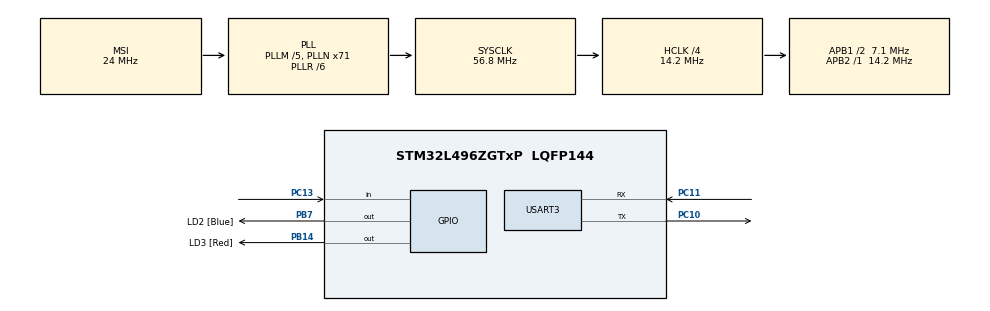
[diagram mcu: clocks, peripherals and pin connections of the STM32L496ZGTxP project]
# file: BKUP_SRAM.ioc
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Mcu.Family=STM32L4
Mcu.Name=STM32L496ZGTxP
Mcu.Package=LQFP144
NVIC.PriorityGroup=NVIC_PRIORITYGROUP_4
NVIC.USART3_IRQn=true\:0\:0\:false\:false\:true\:true\:true\:true
PA10.GPIO_Label=USB_ID
PA10.Signal=USB_OTG_FS_ID
PA11.GPIO_Label=USB_DM
PA11.Signal=USB_OTG_FS_DM
PA12.GPIO_Label=USB_DP
PA12.Signal=USB_OTG_FS_DP
PA13\ (JTMS/SWDIO).GPIO_Label=TMS
PA13\ (JTMS/SWDIO).Mode=Trace_Asynchronous_SW
PA13\ (JTMS/SWDIO).Signal=SYS_JTMS-SWDIO
PA14\ (JTCK/SWCLK).GPIO_Label=TCK
PA14\ (JTCK/SWCLK).Mode=Trace_Asynchronous_SW
PA14\ (JTCK/SWCLK).Signal=SYS_JTCK-SWCLK
PA8.GPIO_Label=USB_SOF [TP1]
PA8.Signal=USB_OTG_FS_SOF
PA9.GPIO_Label=USB_VBUS
PA9.Signal=USB_OTG_FS_VBUS
PB14.GPIO_Label=LD3 [Red]
PB14.Signal=GPIO_Output
PB3\ (JTDO/TRACESWO).GPIO_Label=SWO
PB3\ (JTDO/TRACESWO).Mode=Trace_Asynchronous_SW
PB3\ (JTDO/TRACESWO).Signal=SYS_JTDO-SWO
PB7.GPIO_Label=LD2 [Blue]
PB7.Signal=GPIO_Output
PC10.Mode=Asynchronous
PC10.Signal=USART3_TX
PC11.Mode=Asynchronous
PC11.Signal=USART3_RX
PC13.Signal=GPIO_Input
PC14-OSC32_IN\ (PC14).Mode=LSE-External-Oscillator
PC14-OSC32_IN\ (PC14).Signal=RCC_OSC32_IN
PC15-OSC32_OUT\ (PC15).Mode=LSE-External-Oscillator
PC15-OSC32_OUT\ (PC15).Signal=RCC_OSC32_OUT
PG7.GPIO_Label=STLK_RX [STM32F103CBT6_PA3]
PG7.Signal=LPUART1_TX
PG8.GPIO_Label=STLK_TX [STM32F103CBT6_PA2]
PG8.Signal=LPUART1_RX
PH0-OSC_IN\ (PH0).GPIO_Label=MCO
PH0-OSC_IN\ (PH0).Signal=RCC_OSC_IN
PH1-OSC_OUT\ (PH1).Signal=RCC_OSC_OUT
ProjectManager.HeapSize=0x200
ProjectManager.StackSize=0x400
ProjectManager.TargetToolchain=STM32CubeIDE
RCC.48MHZClocksFreq_Value=24000000
RCC.ADCFreq_Value=48000000
RCC.AHBCLKDivider=RCC_SYSCLK_DIV4
RCC.AHBFreq_Value=14200000
RCC.APB1CLKDivider=RCC_HCLK_DIV2
RCC.APB1Freq_Value=7100000
RCC.APB1TimFreq_Value=14200000
RCC.APB2Freq_Value=14200000
RCC.APB2TimFreq_Value=14200000
RCC.CortexFreq_Value=14200000
RCC.HCLKFreq_Value=14200000
RCC.HSE_VALUE=8000000
RCC.HSI48_VALUE=48000000
RCC.HSI_VALUE=16000000
RCC.MSIClockRange=RCC_MSIRANGE_9
RCC.MSI_VALUE=24000000
RCC.PLLM=5
RCC.PLLMUL=RCC_PLL_MUL9
RCC.PLLN=71
RCC.PLLR=RCC_PLLR_DIV6
RCC.PLLSAI1N=20
RCC.PRESCALERUSB=RCC_USBCLKSOURCE_PLL_DIV1_5
RCC.SYSCLKFreq_VALUE=56800000
RCC.SYSCLKSource=RCC_SYSCLKSOURCE_PLLCLK
RCC.SYSCLKSourceVirtual=RCC_SYSCLKSOURCE_PLLCLK
RCC.USBFreq_Value=48000000
RCC.VCOOutputFreq_Value=340800000
USART3.VirtualMode-Asynchronous=VM_ASYNC
VP_RTC_VS_RTC_Activate.Mode=RTC_Enabled
board=NUCLEO-L496ZG-P

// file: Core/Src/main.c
/* USER CODE BEGIN Header */
/**
  ******************************************************************************
  * @file           : main.c
  * @brief          : Main program body
  ******************************************************************************
  * @attention
  *
  * Copyright (c) 2023 STMicroelectronics.
  * All rights reserved.
  *
  * This software is licensed under terms that can be found in the LICENSE file
  * in the root directory of this software component.
  * If no LICENSE file comes with this software, it is provided AS-IS.
  *
  ******************************************************************************
  */
/* USER CODE END Header */
#include "main.h"

/* USER CODE BEGIN Includes */
#include<string.h>
/* USER CODE END Includes */

RTC_HandleTypeDef hrtc;

UART_HandleTypeDef huart3;

void SystemClock_Config(void);
static void MX_GPIO_Init(void);
static void MX_USART3_UART_Init(void);
static void MX_RTC_Init(void);

int main(void)
{
  /* USER CODE BEGIN 1 */
//uint32_t *pBackupSRAMbase;
char msg[100]="Application is Running\r\n";

  /* USER CODE END 1 */

  /* MCU Configuration--------------------------------------------------------*/

  /* Reset of all peripherals, Initializes the Flash interface and the Systick. */
  HAL_Init();

  /* Configure the system clock */
  SystemClock_Config();

  /* Initialize all configured peripherals */
  MX_GPIO_Init();
  MX_USART3_UART_Init();
  MX_RTC_Init();
  /* USER CODE BEGIN 2 */
HAL_UART_Transmit(&huart3, (uint8_t*)(msg), strlen(msg), HAL_MAX_DELAY);

if (HAL_RTCEx_BKUPRead(&hrtc, RTC_BKP_DR1) != 0xBEBE)
    {
       // Write Back Up Register 1 Data
       HAL_PWR_EnableBkUpAccess();
       // Writes a data in a RTC Backup data Register 1
       HAL_RTCEx_BKUPWrite(&hrtc, RTC_BKP_DR1, 0xBEBE);

HAL_PWR_DisableBkUpAccess();

       //Turn LED2
       HAL_GPIO_WritePin(GPIOB, LD2_Pin, GPIO_PIN_SET);
       strcpy(msg,"LED2\r\n");
       HAL_UART_Transmit(&huart3, (uint8_t*)(msg), strlen(msg), HAL_MAX_DELAY);

    }
    else
    {
       // data register already written so turn LED3
       HAL_GPIO_WritePin(GPIOB, LD3_Pin, GPIO_PIN_SET);
       strcpy(msg,"LED3\r\n");
       HAL_UART_Transmit(&huart3, (uint8_t*)(msg), strlen(msg), HAL_MAX_DELAY);

    }

/* USER CODE END 2 */
  /* Infinite loop */
  while (1)
  {

  }
}

void SystemClock_Config(void)
{
  RCC_OscInitTypeDef RCC_OscInitStruct = {0};
  RCC_ClkInitTypeDef RCC_ClkInitStruct = {0};

  /** Configure the main internal regulator output voltage
  */
  if (HAL_PWREx_ControlVoltageScaling(PWR_REGULATOR_VOLTAGE_SCALE1) != HAL_OK)
  {
    Error_Handler();
  }

  /** Initializes the RCC Oscillators according to the specified parameters
  * in the RCC_OscInitTypeDef structure.
  */
  RCC_OscInitStruct.OscillatorType = RCC_OSCILLATORTYPE_LSI|RCC_OSCILLATORTYPE_MSI;
  RCC_OscInitStruct.LSIState = RCC_LSI_ON;
  RCC_OscInitStruct.MSIState = RCC_MSI_ON;
  RCC_OscInitStruct.MSICalibrationValue = 0;
  RCC_OscInitStruct.MSIClockRange = RCC_MSIRANGE_9;
  RCC_OscInitStruct.PLL.PLLState = RCC_PLL_ON;
  RCC_OscInitStruct.PLL.PLLSource = RCC_PLLSOURCE_MSI;
  RCC_OscInitStruct.PLL.PLLM = 5;
  RCC_OscInitStruct.PLL.PLLN = 71;
  RCC_OscInitStruct.PLL.PLLP = RCC_PLLP_DIV2;
  RCC_OscInitStruct.PLL.PLLQ = RCC_PLLQ_DIV2;
  RCC_OscInitStruct.PLL.PLLR = RCC_PLLR_DIV6;
  if (HAL_RCC_OscConfig(&RCC_OscInitStruct) != HAL_OK)
  {
    Error_Handler();
  }

  /** Initializes the CPU, AHB and APB buses clocks
  */
  RCC_ClkInitStruct.ClockType = RCC_CLOCKTYPE_HCLK|RCC_CLOCKTYPE_SYSCLK
                              |RCC_CLOCKTYPE_PCLK1|RCC_CLOCKTYPE_PCLK2;
  RCC_ClkInitStruct.SYSCLKSource = RCC_SYSCLKSOURCE_PLLCLK;
  RCC_ClkInitStruct.AHBCLKDivider = RCC_SYSCLK_DIV4;
  RCC_ClkInitStruct.APB1CLKDivider = RCC_HCLK_DIV2;
  RCC_ClkInitStruct.APB2CLKDivider = RCC_HCLK_DIV1;

  if (HAL_RCC_ClockConfig(&RCC_ClkInitStruct, FLASH_LATENCY_0) != HAL_OK)
  {
    Error_Handler();
  }
}

static void MX_RTC_Init(void)
{

  /** Initialize RTC Only
  */
  hrtc.Instance = RTC;
  hrtc.Init.HourFormat = RTC_HOURFORMAT_24;
  hrtc.Init.AsynchPrediv = 127;
  hrtc.Init.SynchPrediv = 255;
  hrtc.Init.OutPut = RTC_OUTPUT_DISABLE;
  hrtc.Init.OutPutRemap = RTC_OUTPUT_REMAP_NONE;
  hrtc.Init.OutPutPolarity = RTC_OUTPUT_POLARITY_HIGH;
  hrtc.Init.OutPutType = RTC_OUTPUT_TYPE_OPENDRAIN;
  if (HAL_RTC_Init(&hrtc) != HAL_OK)
  {
    Error_Handler();
  }

}

static void MX_USART3_UART_Init(void)
{

  huart3.Instance = USART3;
  huart3.Init.BaudRate = 115200;
  huart3.Init.WordLength = UART_WORDLENGTH_8B;
  huart3.Init.StopBits = UART_STOPBITS_1;
  huart3.Init.Parity = UART_PARITY_NONE;
  huart3.Init.Mode = UART_MODE_TX_RX;
  huart3.Init.HwFlowCtl = UART_HWCONTROL_NONE;
  huart3.Init.OverSampling = UART_OVERSAMPLING_16;
  huart3.Init.OneBitSampling = UART_ONE_BIT_SAMPLE_DISABLE;
  huart3.AdvancedInit.AdvFeatureInit = UART_ADVFEATURE_NO_INIT;
  if (HAL_UART_Init(&huart3) != HAL_OK)
  {
    Error_Handler();
  }

}

static void MX_GPIO_Init(void)
{
  GPIO_InitTypeDef GPIO_InitStruct = {0};

  /* GPIO Ports Clock Enable */
  __HAL_RCC_GPIOC_CLK_ENABLE();
  __HAL_RCC_GPIOH_CLK_ENABLE();
  __HAL_RCC_GPIOB_CLK_ENABLE();
  __HAL_RCC_GPIOG_CLK_ENABLE();
  HAL_PWREx_EnableVddIO2();
  __HAL_RCC_GPIOA_CLK_ENABLE();

  /*Configure GPIO pin Output Level */
  HAL_GPIO_WritePin(GPIOB, LD3_Pin|LD2_Pin, GPIO_PIN_RESET);

  /*Configure GPIO pin : PC13 */
  GPIO_InitStruct.Pin = GPIO_PIN_13;
  GPIO_InitStruct.Mode = GPIO_MODE_INPUT;
  GPIO_InitStruct.Pull = GPIO_NOPULL;
  HAL_GPIO_Init(GPIOC, &GPIO_InitStruct);

  /*Configure GPIO pins : LD3_Pin LD2_Pin */
  GPIO_InitStruct.Pin = LD3_Pin|LD2_Pin;
  GPIO_InitStruct.Mode = GPIO_MODE_OUTPUT_PP;
  GPIO_InitStruct.Pull = GPIO_NOPULL;
  GPIO_InitStruct.Speed = GPIO_SPEED_FREQ_LOW;
  HAL_GPIO_Init(GPIOB, &GPIO_InitStruct);

  /*Configure GPIO pins : STLK_RX_Pin STLK_TX_Pin */
  GPIO_InitStruct.Pin = STLK_RX_Pin|STLK_TX_Pin;
  GPIO_InitStruct.Mode = GPIO_MODE_AF_PP;
  GPIO_InitStruct.Pull = GPIO_NOPULL;
  GPIO_InitStruct.Speed = GPIO_SPEED_FREQ_VERY_HIGH;
  GPIO_InitStruct.Alternate = GPIO_AF8_LPUART1;
  HAL_GPIO_Init(GPIOG, &GPIO_InitStruct);

  /*Configure GPIO pins : USB_SOF_Pin USB_ID_Pin USB_DM_Pin USB_DP_Pin */
  GPIO_InitStruct.Pin = USB_SOF_Pin|USB_ID_Pin|USB_DM_Pin|USB_DP_Pin;
  GPIO_InitStruct.Mode = GPIO_MODE_AF_PP;
  GPIO_InitStruct.Pull = GPIO_NOPULL;
  GPIO_InitStruct.Speed = GPIO_SPEED_FREQ_VERY_HIGH;
  GPIO_InitStruct.Alternate = GPIO_AF10_OTG_FS;
  HAL_GPIO_Init(GPIOA, &GPIO_InitStruct);

}

void Error_Handler(void)
{
  __disable_irq();
  while (1)
  {
  }
}
